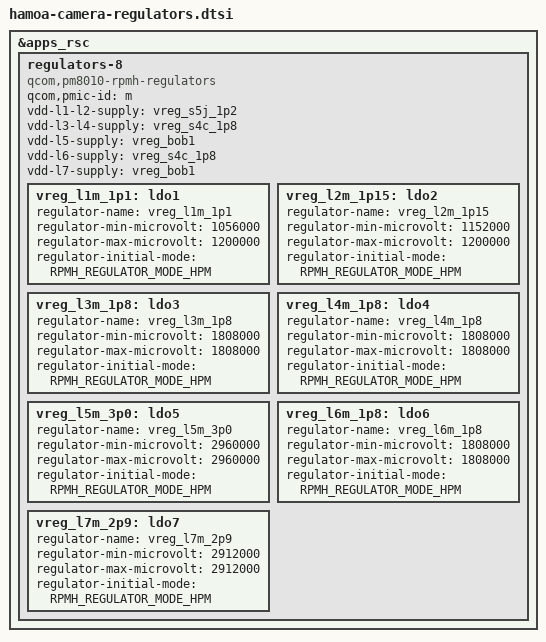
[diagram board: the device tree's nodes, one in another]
// SPDX-License-Identifier: BSD-3-Clause
/*
 * Copyright (c) Qualcomm Technologies, Inc. and/or its subsidiaries.
 */

#include <dt-bindings/regulator/qcom,rpmh-regulator.h>

&apps_rsc {
	/* PM8010_M */
	regulators-8 {
		compatible = "qcom,pm8010-rpmh-regulators";
		qcom,pmic-id = "m";

		vdd-l1-l2-supply = <&vreg_s5j_1p2>;
		vdd-l3-l4-supply = <&vreg_s4c_1p8>;
		vdd-l5-supply = <&vreg_bob1>;
		vdd-l6-supply = <&vreg_s4c_1p8>;
		vdd-l7-supply = <&vreg_bob1>;

		vreg_l1m_1p1: ldo1 {
			regulator-name = "vreg_l1m_1p1";
			regulator-min-microvolt = <1056000>;
			regulator-max-microvolt = <1200000>;
			regulator-initial-mode = <RPMH_REGULATOR_MODE_HPM>;
		};

		vreg_l2m_1p15: ldo2 {
			regulator-name = "vreg_l2m_1p15";
			regulator-min-microvolt = <1152000>;
			regulator-max-microvolt = <1200000>;
			regulator-initial-mode = <RPMH_REGULATOR_MODE_HPM>;
		};

		vreg_l3m_1p8: ldo3 {
			regulator-name = "vreg_l3m_1p8";
			regulator-min-microvolt = <1808000>;
			regulator-max-microvolt = <1808000>;
			regulator-initial-mode = <RPMH_REGULATOR_MODE_HPM>;
		};

		vreg_l4m_1p8: ldo4 {
			regulator-name = "vreg_l4m_1p8";
			regulator-min-microvolt = <1808000>;
			regulator-max-microvolt = <1808000>;
			regulator-initial-mode = <RPMH_REGULATOR_MODE_HPM>;
		};

		vreg_l5m_3p0: ldo5 {
			regulator-name = "vreg_l5m_3p0";
			regulator-min-microvolt = <2960000>;
			regulator-max-microvolt = <2960000>;
			regulator-initial-mode = <RPMH_REGULATOR_MODE_HPM>;
		};

		vreg_l6m_1p8: ldo6 {
			regulator-name = "vreg_l6m_1p8";
			regulator-min-microvolt = <1808000>;
			regulator-max-microvolt = <1808000>;
			regulator-initial-mode = <RPMH_REGULATOR_MODE_HPM>;
		};

		vreg_l7m_2p9: ldo7 {
			regulator-name = "vreg_l7m_2p9";
			regulator-min-microvolt = <2912000>;
			regulator-max-microvolt = <2912000>;
			regulator-initial-mode = <RPMH_REGULATOR_MODE_HPM>;
		};
	};
};
